# ATmega324PB register map
Vendor: Atmel; File version: 1.0
CPU: other r0p0, little endian, no MPU, no FPU, 4 interrupt priority bits
Registers are 8-bit, read-write, reset 0x0 unless marked. A register's access mark holds for its fields unless they carry their own. Offsets are from the block's base; [hi:lo] are bit positions.

## SPI0 — Serial Peripheral Interface
Base 0x0000004C
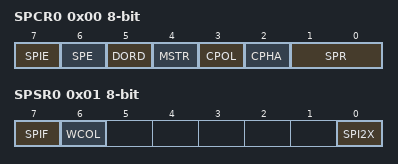
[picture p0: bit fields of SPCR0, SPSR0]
0x00 SPCR0 — SPI Control Register
  [7] SPIE — SPI Interrupt Enable
  [6] SPE — SPI Enable
  [5] DORD — Data Order
  [4] MSTR — Master/Slave Select
  [3] CPOL — Clock polarity
  [2] CPHA — Clock Phase
  [1:0] SPR — SPI Clock Rate Select
    0=FOSC_4; 1=FOSC_16; 3=FOSC_128
0x01 SPSR0 — SPI Status Register
  [7] SPIF — SPI Interrupt Flag
  [6] WCOL — Write Collision Flag
  [0] SPI2X — Double SPI Speed Bit
0x02 SPDR0 — SPI Data Register

## SPI1 — Serial Peripheral Interface
Base 0x000000AC
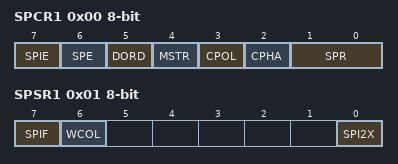
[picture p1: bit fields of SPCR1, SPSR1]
0x00 SPCR1 — SPI Control Register
  [7] SPIE — SPI Interrupt Enable
  [6] SPE — SPI Enable
  [5] DORD — Data Order
  [4] MSTR — Master/Slave Select
  [3] CPOL — Clock polarity
  [2] CPHA — Clock Phase
  [1:0] SPR — SPI Clock Rate Select
    0=FOSC_4; 1=FOSC_16; 3=FOSC_128
0x01 SPSR1 — SPI Status Register
  [7] SPIF — SPI Interrupt Flag
  [6] WCOL — Write Collision Flag
  [0] SPI2X — Double SPI Speed Bit
0x02 SPDR1 — SPI Data Register

## TC0 — Timer/Counter, 8-bit
Base 0x00000035
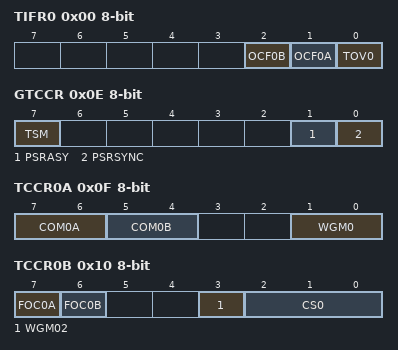
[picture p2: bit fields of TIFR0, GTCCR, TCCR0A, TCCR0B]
0x00 TIFR0 — Timer/Counter0 Interrupt Flag register
  [2] OCF0B — Timer/Counter0 Output Compare Flag 0B
  [1] OCF0A — Timer/Counter0 Output Compare Flag 0A
  [0] TOV0 — Timer/Counter0 Overflow Flag
0x0E GTCCR — General Timer/Counter Control Register
  [7] TSM — Timer/Counter Synchronization Mode
  [1] PSRASY — Prescaler Reset Timer/Counter2
  [0] PSRSYNC — Prescaler Reset Timer/Counter1 and Timer/Counter0
0x0F TCCR0A — Timer/Counter0 Control Register A
  [7:6] COM0A — Compare Match Output A Mode
  [5:4] COM0B — Compare Match Output B Mode
  [1:0] WGM0 — Waveform Generation Mode
0x10 TCCR0B — Timer/Counter0 Control Register B
  [7] FOC0A — Force Output Compare A
  [6] FOC0B — Force Output Compare B
  [3] WGM02 — Waveform Generation Mode
  [2:0] CS0 — Clock Select
    0=NO_CLOCK_SOURCE_STOPPED; 1=RUNNING_NO_PRESCALING; 2=RUNNING_CLK_8; 3=RUNNING_CLK_64; 4=RUNNING_CLK_256; 5=RUNNING_CLK_1024; 6=RUNNING_EXTCLK_TN_FALLING_EDGE; 7=RUNNING_EXTCLK_TN_RISING_EDGE
0x11 TCNT0 — Timer/Counter0
0x12 OCR0A — Timer/Counter0 Output Compare Register
0x13 OCR0B — Timer/Counter0 Output Compare Register
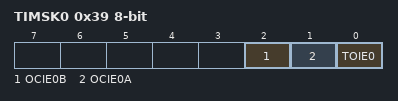
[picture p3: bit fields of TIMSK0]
0x39 TIMSK0 — Timer/Counter0 Interrupt Mask Register
  [2] OCIE0B — Timer/Counter0 Output Compare Match B Interrupt Enable
  [1] OCIE0A — Timer/Counter0 Output Compare Match A Interrupt Enable
  [0] TOIE0 — Timer/Counter0 Overflow Interrupt Enable

## TC1 — Timer/Counter, 16-bit
Base 0x00000036
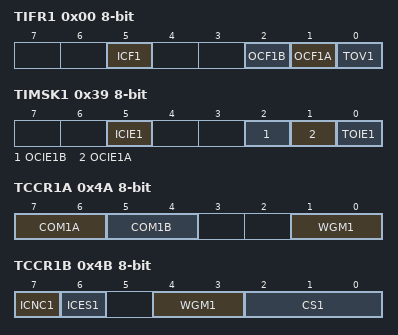
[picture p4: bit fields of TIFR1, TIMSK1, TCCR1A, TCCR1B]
0x00 TIFR1 — Timer/Counter Interrupt Flag register
  [5] ICF1 — Timer/Counter1 Input Capture Flag
  [2] OCF1B — Timer/Counter1 Output Compare B Match Flag
  [1] OCF1A — Timer/Counter1 Output Compare A Match Flag
  [0] TOV1 — Timer/Counter1 Overflow Flag
0x39 TIMSK1 — Timer/Counter1 Interrupt Mask Register
  [5] ICIE1 — Timer/Counter1 Input Capture Interrupt Enable
  [2] OCIE1B — Timer/Counter1 Output Compare B Match Interrupt Enable
  [1] OCIE1A — Timer/Counter1 Output Compare A Match Interrupt Enable
  [0] TOIE1 — Timer/Counter1 Overflow Interrupt Enable
0x4A TCCR1A — Timer/Counter1 Control Register A
  [7:6] COM1A — Compare Output Mode 1A, bits
  [5:4] COM1B — Compare Output Mode 1B, bits
  [1:0] WGM1 — Pulse Width Modulator Select Bits
0x4B TCCR1B — Timer/Counter1 Control Register B
  [7] ICNC1 — Input Capture 1 Noise Canceler
  [6] ICES1 — Input Capture 1 Edge Select
  [4:3] WGM1 — Waveform Generation Mode Bits
  [2:0] CS1 — Clock Select1 bits
    0=NO_CLOCK_SOURCE_STOPPED; 1=RUNNING_NO_PRESCALING; 2=RUNNING_CLK_8; 3=RUNNING_CLK_64; 4=RUNNING_CLK_256; 5=RUNNING_CLK_1024; 6=RUNNING_EXTCLK_TN_FALLING_EDGE; 7=RUNNING_EXTCLK_TN_RISING_EDGE
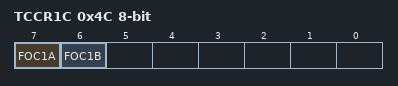
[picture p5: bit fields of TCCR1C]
0x4C TCCR1C — Timer/Counter1 Control Register C
  [7] FOC1A — Force Output Compare for Channel A
  [6] FOC1B — Force Output Compare for Channel B
0x4E TCNT1 16-bit (reset mask 0xFF) — Timer/Counter1 Bytes
0x50 ICR1 16-bit (reset mask 0xFF) — Timer/Counter1 Input Capture Register Bytes
0x52 OCR1A 16-bit (reset mask 0xFF) — Timer/Counter1 Output Compare Register A Bytes
0x54 OCR1B 16-bit (reset mask 0xFF) — Timer/Counter1 Output Compare Register B Bytes
